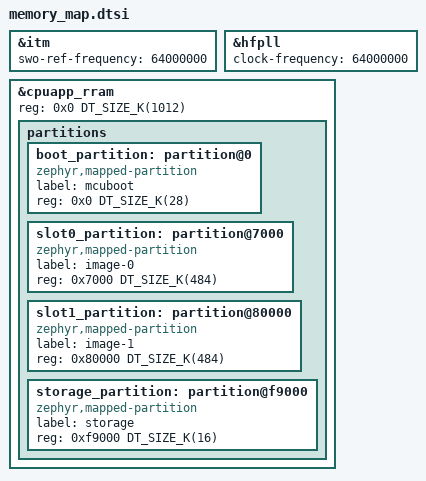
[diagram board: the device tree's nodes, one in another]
/*
 * Copyright (c) 2026 Nordic Semiconductor ASA
 *
 * SPDX-License-Identifier: LicenseRef-Nordic-5-Clause
 */

/*
 * nRF54L Series SoCs start at 64 MHz and may switch to 128 MHz during init.
 * Zephyr sets 128 MHz at boot by default (SoC-level devicetree).
 * 64 MHz is enough for 1000 Hz HID reporting and lowers power vs 128 MHz.
 */


&itm {
	swo-ref-frequency = <64000000>;
};

&hfpll {
	clock-frequency = <64000000>;
};

&cpuapp_rram {
	/* Application does not use cpuflpr core. Assign whole RRAM to cpuapp. */
	reg = <0x0 DT_SIZE_K(1012)>;

	/delete-node/ partitions;

	partitions {
		#address-cells = <1>;
		#size-cells = <1>;
		ranges;

		boot_partition: partition@0 {
			compatible = "zephyr,mapped-partition";
			label = "mcuboot";
			reg = <0x0 DT_SIZE_K(28)>;
		};

		slot0_partition: partition@7000 {
			compatible = "zephyr,mapped-partition";
			label = "image-0";
			reg = <0x7000 DT_SIZE_K(484)>;
		};

		slot1_partition: partition@80000 {
			compatible = "zephyr,mapped-partition";
			label = "image-1";
			reg = <0x80000 DT_SIZE_K(484)>;
		};

		storage_partition: partition@f9000 {
			compatible = "zephyr,mapped-partition";
			label = "storage";
			reg = <0xf9000 DT_SIZE_K(16)>;
		};
	};
};
